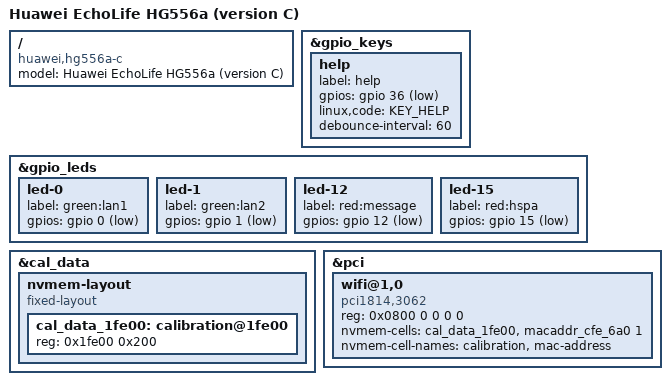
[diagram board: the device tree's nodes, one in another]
// SPDX-License-Identifier: GPL-2.0-or-later

#include "bcm6358-huawei-hg556a.dtsi"

/ {
	model = "Huawei EchoLife HG556a (version C)";
	compatible = "huawei,hg556a-c", "brcm,bcm6358";
};

&gpio_keys {
	help {
		label = "help";
		gpios = <&gpio 36 GPIO_ACTIVE_LOW>;
		linux,code = <KEY_HELP>;
		debounce-interval = <60>;
	};
};

&gpio_leds {
	led-0 {
		label = "green:lan1";
		gpios = <&gpio 0 GPIO_ACTIVE_LOW>;
	};

	led-1 {
		label = "green:lan2";
		gpios = <&gpio 1 GPIO_ACTIVE_LOW>;
	};

	led-12 {
		label = "red:message";
		gpios = <&gpio 12 GPIO_ACTIVE_LOW>;
	};

	led-15 {
		label = "red:hspa";
		gpios = <&gpio 15 GPIO_ACTIVE_LOW>;
	};
};

&cal_data {
	nvmem-layout {
		compatible = "fixed-layout";
		#address-cells = <1>;
		#size-cells = <1>;

		cal_data_1fe00: calibration@1fe00 {
			reg = <0x1fe00 0x200>;
		};
	};
};

&pci {
	status = "okay";

	wifi@1,0 {
		compatible = "pci1814,3062";
		reg = <0x0800 0 0 0 0>;

		nvmem-cells = <&cal_data_1fe00>, <&macaddr_cfe_6a0 1>;
		nvmem-cell-names = "calibration", "mac-address";
	};
};
